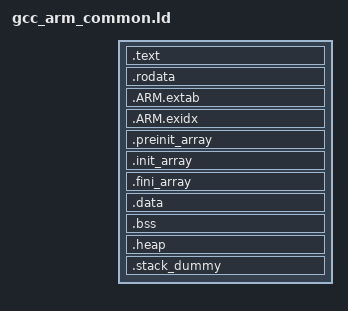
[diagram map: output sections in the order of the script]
OUTPUT_FORMAT ("elf32-littlearm", "elf32-bigarm", "elf32-littlearm")

/* Linker script to place sections and symbol values. Should be used together
 * with other linker script that defines memory regions FLASH and RAM.
 * It references following symbols, which must be defined in code:
 *   Reset_Handler : Entry of reset handler
 *
 * It defines following symbols, which code can use without definition:
 *   __exidx_start
 *   __exidx_end
 *   __etext - end of text section (following this is rodata!)
 *   __end_used_flash - (also accounts for flash used to store .data contents)
 *   __data_start_in_flash - data start address in flash
 *   __data_start__ - data start address in RAM
 *   __preinit_array_start
 *   __preinit_array_end
 *   __init_array_start
 *   __init_array_end
 *   __fini_array_start
 *   __fini_array_end
 *   __data_end__
 *   __bss_start__
 *   __bss_end__
 *   __end__
 *   end
 *   __HeapBase
 *   __HeapLimit
 *   __StackLimit
 *   __StackTop
 *   __stack
 */
ENTRY(Reset_Handler)

SECTIONS
{
    .text :
    {
     	/* Startup code is the first thing in flash/.text */
        KEEP(*(.isr_vector))

        /* Then comes code */
        *(.text*)

        /* Glue ARM to Thumb code */
        *(.glue_7)

        /* Glue Thumb to ARM code */
        *(.glue_7t)

        /* Exception Handling ? */
        KEEP(*(.eh_frame*))
        /* TODO: align 4?
        *(.eh_frame*)

        KEEP(*(.init))
        KEEP(*(.fini))
		. = ALIGN(4);

        /* End of text section */
        __etext = .;
        */
    } > FLASH

    /* Constant data, used for initialization */
    .rodata :
    {
        . = ALIGN(4);
        *(.rodata*)
    } >FLASH

    .ARM.extab :
    {
        *(.ARM.extab* .gnu.linkonce.armextab.*)
    } > FLASH

    __exidx_start = .;
    .ARM.exidx :
    {
        *(.ARM.exidx* .gnu.linkonce.armexidx.*)
    } > FLASH
    __exidx_end = .;

    .preinit_array     :
    {
        . = ALIGN(4);
        PROVIDE_HIDDEN (__preinit_array_start = .);
        KEEP(*(.preinit_array))
        PROVIDE_HIDDEN (__preinit_array_end = .);
    } >FLASH

    .init_array :
    {
        . = ALIGN(4);
        /*
        * TODO: do I need to put the ctors here??
        * KEEP(*(.ctors))
        */
        PROVIDE_HIDDEN (__init_array_start = .);
        KEEP (*(SORT(.init_array.*)))
        KEEP (*(.init_array*))
        PROVIDE_HIDDEN (__init_array_end = .);
    } >FLASH

    .fini_array :
    {
        . = ALIGN(4);
        PROVIDE_HIDDEN (__fini_array_start = .);
        KEEP (*(SORT(.fini_array.*)))
        KEEP (*(.fini_array*))
        PROVIDE_HIDDEN (__fini_array_end = .);
    } >FLASH

    __data_start_in_flash = .;

    .data : AT (__etext)
    {
        . = ALIGN(4);
        __data_start__ = .;
        *(vtable)
        *(.data)
        *(.data*)
        . = ALIGN(4);

        /* All data end */
        __data_end__ = .;
    } > RAM

    __end_used_flash = __data_start_in_flash + SIZEOF(.data);

    .bss :
    {
        . = ALIGN(4);
        __bss_start__ = .;
        *(.bss*)
        *(COMMON)
        . = ALIGN(4);
        __bss_end__ = .;
    } > RAM

    .heap (COPY):
    {
        __HeapBase = .;
        __end__ = .;
        PROVIDE(end = .);
        KEEP(*(.heap*))
        __HeapLimit = .;
    } > RAM

    /* .stack_dummy section doesn't contains any symbols. It is only
     * used for linker to calculate size of stack sections, and assign
     * values to stack symbols later */
    .stack_dummy (COPY):
    {
        KEEP(*(.stack*))
    } > RAM

    /* Set stack top to end of RAM, and stack limit move down by
     * size of stack_dummy section */
    __StackTop = ORIGIN(RAM) + LENGTH(RAM);
    __StackLimit = __StackTop - SIZEOF(.stack_dummy);
    PROVIDE(__stack = __StackTop);

    /* Check if data + heap + stack exceeds RAM limit */
    ASSERT(__StackLimit >= __HeapLimit, "region RAM overflowed with stack")

    /* Check if text sections + data exceeds FLASH limit */
    DataInitFlashUsed = __bss_start__ - __data_start__;
    CodeFlashUsed = __end_used_flash - ORIGIN(FLASH);
    TotalFlashUsed = CodeFlashUsed + DataInitFlashUsed;
    ASSERT(TotalFlashUsed <= LENGTH(FLASH), "region FLASH overflowed with .data and user data")

}
